# CY8C5888LTI_LP097 register map
File version: 0.1
CY8C58LP
Registers are 8-bit, read-write, no defined reset value unless marked. A register's access mark holds for its fields unless they carry their own. Offsets are from the block's base; lines under a group give offsets from that group; [hi:lo] are bit positions; {n}, {i} and the like mark numbered series; 'fields as' and 'values as' point back to an identical list; <NAME> marks a mode.

## Memory map
0x00000000 IVO
0x00000000 no_fb_reg
0x00000000 ADC_peak — SAR ADC
0x00000000 interrupterTimebase
0x00000000 Amux_Ctrl
0x00000000 ZCD_counter
0x00000000 CT1_dac
0x00000000 ZCD_compA
0x00000000 Opamp_2
0x00000000 USBUART_1 — USBFS
0x00000000 Opamp_1
0x00000000 UART
0x00000000 Sample_Hold_1
0x00000000 CT1_comp
0x00000000 Comp_1
0x00000000 OnTimeCounter
0x00000000 I2C
0x00000000 temp_pwm
0x00000000 FB_Filter
0x00000000 interrupter1
0x00000000 ADC — SAR ADC
0x00000000 PWMB
0x00000000 ZCD_compB
0x00000000 interrupter1_control
0x00000000 system_fault
0x00000000 IDAC_therm
0x00000000 ZCDref
0x00000000 PWMA
0x00000000 ADC_therm
0x00000000 FB_THRSH_DAC
0x00000000 FB_capture
0x00000000 FB_glitch_detect
0x00000000 QCW_enable

## IVO
Base 0x00000000
0x40006577 IVO_CONTROL_REG

## no_fb_reg
Base 0x00000000
0x4000646E no_fb_reg_STATUS_REG
0x4000648E no_fb_reg_MASK_REG
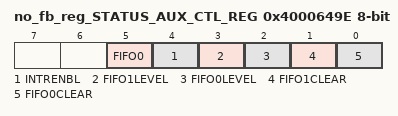
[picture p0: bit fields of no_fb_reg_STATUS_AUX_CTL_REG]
0x4000649E no_fb_reg_STATUS_AUX_CTL_REG
  [5] FIFO0 — FIFO0 clear
    1=ENABLED (Enable counter); 0=DISABLED (Disable counter)
  [4] INTRENBL — Enables or disables the Interrupt
    1=ENABLED (Interrupt enabled); 0=DISABLED (Interrupt disabled)
  [3] FIFO1LEVEL — FIFO level
    1=ENABLED (FIFO LVL: input mode: FIFO at least 1/2 empty; output mode: FIFO at least 1/2 full); 0=DISABLED (FIFO LVL: input mode: FIFO not full; output mode: FIFO not empty)
  [2] FIFO0LEVEL — FIFO level
    values as FIFO1LEVEL
  [1] FIFO1CLEAR — FIFO clear
    1=ENABLED (Clear FIFO state); 0=DISABLED (Normal FIFO operation)
  [0] FIFO0CLEAR — FIFO clear
    values as FIFO1CLEAR

## ADC_peak — SAR ADC
Base 0x00000000
0x40004614 SAR_TR0 — SAR trim register
{0x40005900+i} SAR_CSR{i} (i=0..6) — SAR status and control register {i}
0x40005B20 SAR_SW0 — SAR Analog Routing Register 0
{0x40005B20+i} SAR_SW{i} (i=2..4) — SAR Analog Routing Register {i}
0x40005B26 SAR_SW6 — SAR Analog Routing Register 6
0x40005B27 SAR_CLK — SAR Clock Selection Register
0x40005BA0 SAR_WRK 16-bit — SAR working register

## interrupterTimebase
Base 0x00000000
0x40006408 interrupterTimebase_COUNTER 32-bit — UDB.A0 - Current Counter Value
0x40006428 interrupterTimebase_PERIOD 32-bit — UDB.D0 - Assigned Period
0x40006438 interrupterTimebase_COMPARE 32-bit — UDB.D1 - Assigned Compare Value
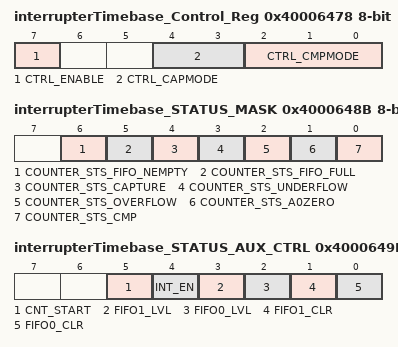
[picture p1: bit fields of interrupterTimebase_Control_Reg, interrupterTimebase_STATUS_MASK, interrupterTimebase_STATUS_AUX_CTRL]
0x40006478 interrupterTimebase_Control_Reg — UDB Control Register - Assigned Control Register Value
  [7] CTRL_ENABLE — Enable Counter
  [4:3] CTRL_CAPMODE — Capture mode
  [2:0] CTRL_CMPMODE — Compare mode
0x4000648B interrupterTimebase_STATUS_MASK — UDB Status bits Interrupt Mask Enable Register
  [6] COUNTER_STS_FIFO_NEMPTY — FIFO Not Empty Status
  [5] COUNTER_STS_FIFO_FULL — FIFO Full Status
  [4] COUNTER_STS_CAPTURE — Capture Status
  [3] COUNTER_STS_UNDERFLOW — Underflow status
  [2] COUNTER_STS_OVERFLOW — Overflow status
  [1] COUNTER_STS_A0ZERO — A0 Zero ouput status
  [0] COUNTER_STS_CMP — Compare output status
0x4000649B interrupterTimebase_STATUS_AUX_CTRL — UDB Auxilliary Control Register
  [5] CNT_START — FIFO0 clear
    0=E_CNT_START0 (Disable counter); 1=E_CNT_START1 (Enable counter)
  [4] INT_EN
    0=E_INT_EN0 (Interrupt disabled); 1=E_INT_EN1 (Interrupt enabled)
  [3] FIFO1_LVL — FIFO level
    0=E_FIFO_LVL_0 (FIFO LVL: input mode: FIFO not full; output mode: FIFO not empty); 1=E_FIFO_LVL_1 (FIFO LVL: input mode: FIFO at least 1/2 empty; output mode: FIFO at least 1/2 full)
  [2] FIFO0_LVL — FIFO level
    values as FIFO1_LVL
  [1] FIFO1_CLR — FIFO1 clear
    0=E_FIFO_CLR_0 (Normal FIFO operation); 1=E_FIFO_CLR_1 (Clear FIFO state)
  [0] FIFO0_CLR — FIFO0 clear
    values as FIFO1_CLR
